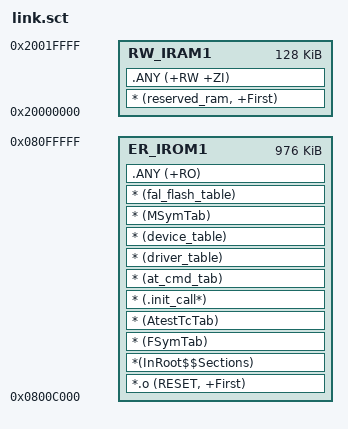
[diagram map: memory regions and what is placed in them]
; *************************************************************
; *** Scatter-Loading Description File generated by uVision ***
; *************************************************************

LR_IROM1 0x0800c000 0x000f4000  {    ; load region size_region
  ER_IROM1 0x0800c000 0x000f4000  {  ; load address = execution address
   *.o (RESET, +First)
   *(InRoot$$Sections)
   * (FSymTab)
   * (AtestTcTab)
   * (.init_call*)
   * (at_cmd_tab)
   * (driver_table)
   * (device_table)
   * (MSymTab)
   * (fal_flash_table)
   .ANY (+RO)
  }
  RW_IRAM1 0x20000000 0x00020000  {  ; RW data
   * (reserved_ram, +First)
   .ANY (+RW +ZI)
  }
}

;STM32F407VG
